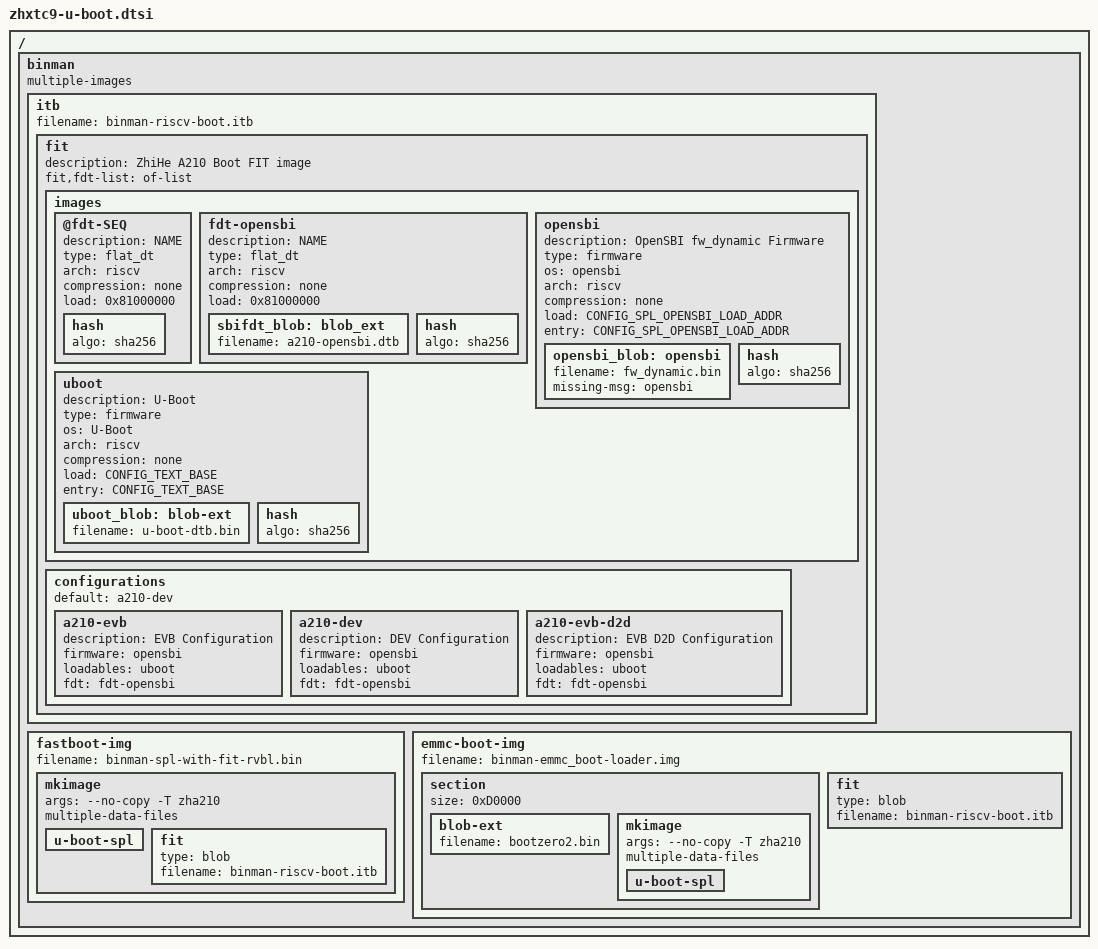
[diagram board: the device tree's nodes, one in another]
// SPDX-License-Identifier: GPL-2.0-only
/*
 * Copyright (c) 2025 Hangfan Li <lihangfan@iscas.ac.cn>
 */

#include <config.h>

/ {
	binman: binman {
		multiple-images;
	};
};

&binman {
	itb {
		filename = "binman-riscv-boot.itb";
		fit {
			description = "ZhiHe A210 Boot FIT image";
			#address-cells = <1>;
			fit,fdt-list = "of-list";

			images {
				@fdt-SEQ {
					description = "NAME";
					type = "flat_dt";
					arch = "riscv";
					compression = "none";
					load = /bits/ 64 <0x81000000>;

					hash {
						algo = "sha256";
					};
				};

				fdt-opensbi {
					description = "NAME";
					type = "flat_dt";
					arch = "riscv";
					compression = "none";
					load = /bits/ 64 <0x81000000>;

					sbifdt_blob: blob_ext {
						filename = "a210-opensbi.dtb";
					};

					hash {
						algo = "sha256";
					};
				};

				opensbi {
					description = "OpenSBI fw_dynamic Firmware";
					type = "firmware";
					os = "opensbi";
					arch = "riscv";
					compression = "none";
					load = /bits/ 64 <CONFIG_SPL_OPENSBI_LOAD_ADDR>;
					entry = /bits/ 64 <CONFIG_SPL_OPENSBI_LOAD_ADDR>;

					opensbi_blob: opensbi {
						filename = "fw_dynamic.bin";
						missing-msg = "opensbi";
					};


					hash {
						algo = "sha256";
					};
				};

				uboot {
					description = "U-Boot";
					type = "firmware";
					os = "U-Boot";
					arch = "riscv";
					compression = "none";
					load = /bits/ 64 <CONFIG_TEXT_BASE>;
					entry = /bits/ 64 <CONFIG_TEXT_BASE>;

					uboot_blob: blob-ext {
						filename = "u-boot-dtb.bin";
					};

					hash {
						algo = "sha256";
					};
				};
			};

			configurations {
				default = "a210-dev";

				a210-evb {
					description = "EVB Configuration";
					firmware = "opensbi";
					loadables = "uboot";
					fdt = "fdt-opensbi";
				};

				a210-dev {
					description = "DEV Configuration";
					firmware = "opensbi";
					loadables = "uboot";
					fdt = "fdt-opensbi";
				};

				a210-evb-d2d {
					description = "EVB D2D Configuration";
					firmware = "opensbi";
					loadables = "uboot";
					fdt = "fdt-opensbi";
				};
			};
		};
	};

	fastboot-img {
		filename = "binman-spl-with-fit-rvbl.bin";

		mkimage {
			args = "--no-copy -T zha210";
			multiple-data-files;

			u-boot-spl {
			};

			fit {
				type = "blob";
				filename = "binman-riscv-boot.itb";
			};
		};
	};

	emmc-boot-img {
		filename = "binman-emmc_boot-loader.img";

		section {
			size = <0xD0000>;

			blob-ext {
				filename = "bootzero2.bin";
			};

			mkimage {
				args = "--no-copy -T zha210";
				multiple-data-files;

				u-boot-spl {
				};
			};
		};

		fit {
			type = "blob";
			filename = "binman-riscv-boot.itb";
		};
	};
};
